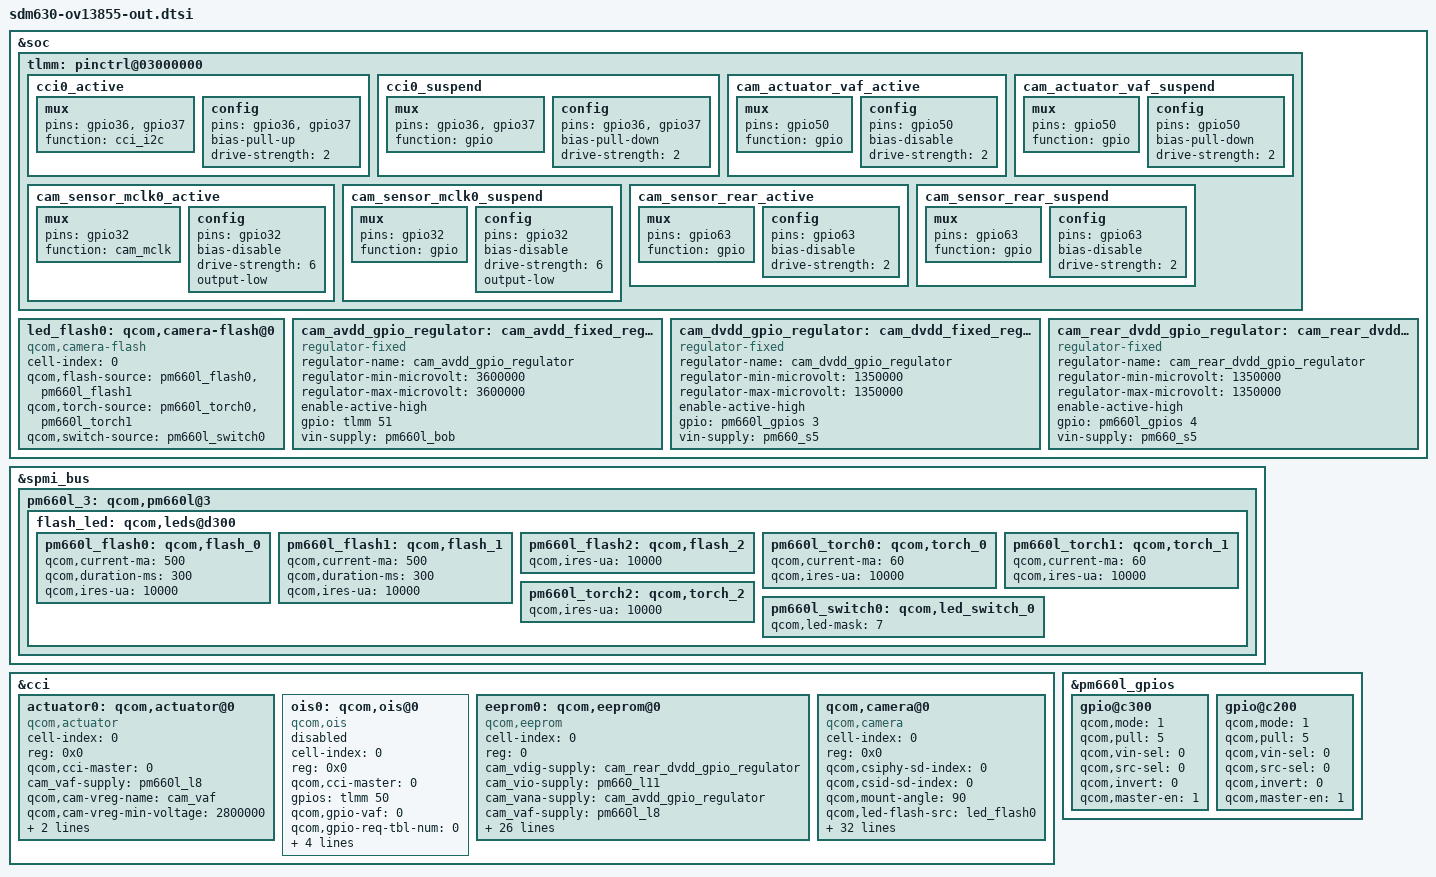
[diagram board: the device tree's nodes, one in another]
/*
 * This software is contributed or developed by KYOCERA Corporation.
 * (C) 2018 KYOCERA Corporation
 *
 * This program is free software; you can redistribute it and/or modify
 * it under the terms of the GNU General Public License version 2 and
 * only version 2 as published by the Free Software Foundation.
 *
 * This program is distributed in the hope that it will be useful,
 * but WITHOUT ANY WARRANTY; without even the implied warranty of
 * MERCHANTABILITY or FITNESS FOR A PARTICULAR PURPOSE.  See the
 * GNU General Public License for more details.
 */

&soc {
	tlmm: pinctrl@03000000 {

		cci0_active: cci0_active {
			mux {
				/* CLK, DATA */
				pins = "gpio36","gpio37"; // Only 2
				function = "cci_i2c";
			};

			config {
				pins = "gpio36","gpio37";
				bias-pull-up; /* PULL UP*/
				drive-strength = <2>; /* 2 MA */
			};
		};

		cci0_suspend: cci0_suspend {
			mux {
				/* CLK, DATA */
				pins = "gpio36","gpio37";
				function = "gpio";
			};

			config {
				pins = "gpio36","gpio37";
				bias-pull-down; /* PULL DOWN */
				drive-strength = <2>; /* 2 MA */
			};
		};

		cam_actuator_vaf_active: cam_actuator_vaf_active {
			/* ACTUATOR POWER */
			mux {
				pins = "gpio50";
				function = "gpio";
			};

			config {
				pins = "gpio50";
				bias-disable; /* No PULL */
				drive-strength = <2>; /* 2 MA */
			};
		};

		cam_actuator_vaf_suspend: cam_actuator_vaf_suspend {
			/* ACTUATOR POWER */
			mux {
				pins = "gpio50";
				function = "gpio";
			};

			config {
				pins = "gpio50";
				bias-pull-down; /* PULL DOWN */
				drive-strength = <2>; /* 2 MA */
			};
		};

		cam_sensor_mclk0_active: cam_sensor_mclk0_active {
			/* MCLK0 */
			mux {
				/* CLK */
				pins = "gpio32";
				function = "cam_mclk";
			};

			config {
				pins = "gpio32";
				bias-disable; /* No PULL */
				drive-strength = <6>; /* 6 MA */
				output-low;
			};
		};

		cam_sensor_mclk0_suspend: cam_sensor_mclk0_suspend {
			/* MCLK0 */
			mux {
				/* CLK */
				pins = "gpio32";
				function = "gpio";
			};

			config {
				pins = "gpio32";
				bias-disable; /* No PULL */
				drive-strength = <6>; /* 6 MA */
				output-low;
			};
		};

		cam_sensor_rear_active: cam_sensor_rear_active {
			/* RESET, STANDBY */
			mux {
				pins = "gpio63";
				function = "gpio";
			};

			config {
				pins = "gpio63";
				bias-disable; /* No PULL */
				drive-strength = <2>; /* 2 MA */
			};
		};

		cam_sensor_rear_suspend: cam_sensor_rear_suspend {
			/* RESET, STANDBY */
			mux {
				pins = "gpio63";
				function = "gpio";
			};

			config {
				pins = "gpio63";
				bias-disable; /* No PULL */
				drive-strength = <2>; /* 2 MA */
			};
		};
	};
};

&spmi_bus {
	pm660l_3: qcom,pm660l@3 {
		flash_led: qcom,leds@d300 {
			pm660l_flash0: qcom,flash_0 {
				qcom,current-ma = <500>;
				qcom,duration-ms = <300>;
				qcom,ires-ua = <10000>;
			};

			pm660l_flash1: qcom,flash_1 {
				qcom,current-ma = <500>;
				qcom,duration-ms = <300>;
				qcom,ires-ua = <10000>;
			};

			pm660l_flash2: qcom,flash_2 {
				qcom,ires-ua = <10000>;
			};

			pm660l_torch0: qcom,torch_0 {
				qcom,current-ma = <60>;
				qcom,ires-ua = <10000>;
			};

			pm660l_torch1: qcom,torch_1 {
				qcom,current-ma = <60>;
				qcom,ires-ua = <10000>;
			};

			pm660l_torch2: qcom,torch_2 {
				qcom,ires-ua = <10000>;
			};

			pm660l_switch0: qcom,led_switch_0 {
				qcom,led-mask = <7>;
			};
		};
	};
};

&soc {
	led_flash0: qcom,camera-flash@0 {
		cell-index = <0>;
		compatible = "qcom,camera-flash";
		qcom,flash-source = <&pm660l_flash0 &pm660l_flash1>;
		qcom,torch-source = <&pm660l_torch0 &pm660l_torch1>;
		qcom,switch-source = <&pm660l_switch0>;
		status = "ok";
	};

	cam_avdd_gpio_regulator: cam_avdd_fixed_regulator {
		compatible = "regulator-fixed";
		regulator-name = "cam_avdd_gpio_regulator";
		regulator-min-microvolt = <3600000>;
		regulator-max-microvolt = <3600000>;
		enable-active-high;
		gpio = <&tlmm 51 0>;
		vin-supply = <&pm660l_bob>;
	};

	cam_dvdd_gpio_regulator: cam_dvdd_fixed_regulator {
		compatible = "regulator-fixed";
		regulator-name = "cam_dvdd_gpio_regulator";
		regulator-min-microvolt = <1350000>;
		regulator-max-microvolt = <1350000>;
		enable-active-high;
		gpio = <&pm660l_gpios 3 0>;
		vin-supply = <&pm660_s5>;
	};

	cam_rear_dvdd_gpio_regulator: cam_rear_dvdd_fixed_regulator {
		compatible = "regulator-fixed";
		regulator-name = "cam_rear_dvdd_gpio_regulator";
		regulator-min-microvolt = <1350000>;
		regulator-max-microvolt = <1350000>;
		enable-active-high;
		gpio = <&pm660l_gpios 4 0>;
		vin-supply = <&pm660_s5>;
	};
};

&cci {
	actuator0: qcom,actuator@0 {
		cell-index = <0>;
		reg = <0x0>;
		compatible = "qcom,actuator";
		qcom,cci-master = <0>;
		cam_vaf-supply = <&pm660l_l8>;
		qcom,cam-vreg-name = "cam_vaf";
		qcom,cam-vreg-min-voltage = <2800000>;
		qcom,cam-vreg-max-voltage = <3400000>;
		qcom,cam-vreg-op-mode = <100000>;
	};

	ois0: qcom,ois@0 {
		cell-index = <0>;
		reg = <0x0>;
		compatible = "qcom,ois";
		qcom,cci-master = <0>;
		gpios = <&tlmm 50 0>;
		qcom,gpio-vaf = <0>;
		qcom,gpio-req-tbl-num = <0>;
		qcom,gpio-req-tbl-flags = <0>;
		qcom,gpio-req-tbl-label = "CAM_VAF";
		pinctrl-names = "cam_default", "cam_suspend";
		pinctrl-0 = <&cam_actuator_vaf_active>;
		pinctrl-1 = <&cam_actuator_vaf_suspend>;
		status = "disabled";
	};

	eeprom0: qcom,eeprom@0 {
		cell-index = <0>;
		reg = <0>;
		compatible = "qcom,eeprom";
		cam_vdig-supply = <&cam_rear_dvdd_gpio_regulator>;
		cam_vio-supply = <&pm660_l11>;
		cam_vana-supply = <&cam_avdd_gpio_regulator>;
		cam_vaf-supply = <&pm660l_l8>;
		qcom,cam-vreg-name = "cam_vdig", "cam_vio", "cam_vana",
					"cam_vaf";
		qcom,cam-vreg-min-voltage = <0 1780000 0 2800000>;
		qcom,cam-vreg-max-voltage = <0 1950000 0 3400000>;
		qcom,cam-vreg-op-mode = <0 105000 0 100000>;
		qcom,gpio-no-mux = <0>;
		pinctrl-names = "cam_default", "cam_suspend";
		pinctrl-0 = <&cam_sensor_mclk0_active
				&cam_sensor_rear_active>;
		pinctrl-1 = <&cam_sensor_mclk0_suspend
				&cam_sensor_rear_suspend>;
		gpios = <&tlmm 32 0>,
			<&tlmm 50 0>,
			<&tlmm 51 0>,
			<&pm660l_gpios 3 0>,
			<&tlmm 63 0>;
		qcom,gpio-vaf = <1>;
		qcom,gpio-vana = <2>;
		qcom,gpio-vdig = <3>;
		qcom,gpio-reset = <4>;
		qcom,gpio-req-tbl-num = <0 1 2 3 4>;
		qcom,gpio-req-tbl-flags = <1 1 1 1 1>;
		qcom,gpio-req-tbl-label = "CAMIF_MCLK0", "CAM_VAF", "CAM_VANA", "CAM_VDIG", "CAM_RESET0";
		qcom,sensor-position = <0>;
		qcom,sensor-mode = <0>;
		qcom,cci-master = <0>;
		status = "ok";
		clocks = <&clock_mmss MCLK0_CLK_SRC>,
				<&clock_mmss MMSS_CAMSS_MCLK0_CLK>;
		clock-names = "cam_src_clk", "cam_clk";
		qcom,clock-rates = <24000000 0>;
	};

	qcom,camera@0 {
		cell-index = <0>;
		compatible = "qcom,camera";
		reg = <0x0>;
		qcom,csiphy-sd-index = <0>;
		qcom,csid-sd-index = <0>;
		qcom,mount-angle = <90>;
		qcom,led-flash-src = <&led_flash0>;
		qcom,actuator-src = <&actuator0>;
		qcom,ois-src = <&ois0>;
		qcom,eeprom-src = <&eeprom0>;
		cam_vdig-supply = <&cam_rear_dvdd_gpio_regulator>;
		cam_vio-supply = <&pm660_l11>;
		cam_vana-supply = <&cam_avdd_gpio_regulator>;
		qcom,cam-vreg-name = "cam_vdig", "cam_vio", "cam_vana";
		qcom,cam-vreg-min-voltage = <0 1780000 0>;
		qcom,cam-vreg-max-voltage = <0 1950000 0>;
		qcom,cam-vreg-op-mode = <0 105000 0>;
		qcom,gpio-no-mux = <0>;
		pinctrl-names = "cam_default", "cam_suspend";
		pinctrl-0 = <&cam_sensor_mclk0_active
				 &cam_sensor_rear_active>;
		pinctrl-1 = <&cam_sensor_mclk0_suspend
				 &cam_sensor_rear_suspend>;
		gpios = <&tlmm 32 0>,
			<&tlmm 50 0>,
			<&tlmm 51 0>,
			<&pm660l_gpios 3 0>,
			<&tlmm 63 0>;
		qcom,gpio-vaf = <1>;
		qcom,gpio-vana = <2>;
		qcom,gpio-vdig = <3>;
		qcom,gpio-reset = <4>;
		qcom,gpio-req-tbl-num = <0 1 2 3 4>;
		qcom,gpio-req-tbl-flags = <1 0 0 0 0>;
		qcom,gpio-req-tbl-label = "CAMIF_MCLK0", "CAM_VAF", "CAM_VANA", "CAM_VDIG", "CAM_RESET0";
		qcom,sensor-position = <0>;
		qcom,sensor-mode = <0>;
		qcom,cci-master = <0>;
		status = "ok";
		clocks = <&clock_mmss MCLK0_CLK_SRC>,
				<&clock_mmss MMSS_CAMSS_MCLK0_CLK>;
		clock-names = "cam_src_clk", "cam_clk";
		qcom,clock-rates = <24000000 0>;
	};
};

&pm660l_gpios {
	gpio@c300 { /* GPIO4 -CAMERA SENSOR 0 VDIG*/
		qcom,mode = <1>;                /* Output */
		qcom,pull = <5>;                /* No Pull */
		qcom,vin-sel = <0>;             /* VIN1 GPIO_LV */
		qcom,src-sel = <0>;             /* GPIO */
		qcom,invert = <0>;              /* Invert */
		qcom,master-en = <1>;           /* Enable GPIO */
		status = "ok";
	};

	gpio@c200 { /* GPIO3 -CAMERA SENSOR 2 VDIG*/
		qcom,mode = <1>;                /* Output */
		qcom,pull = <5>;                /* No Pull */
		qcom,vin-sel = <0>;             /* VIN1 GPIO_LV */
		qcom,src-sel = <0>;             /* GPIO */
		qcom,invert = <0>;              /* Invert */
		qcom,master-en = <1>;           /* Enable GPIO */
		status = "ok";
	};
};
